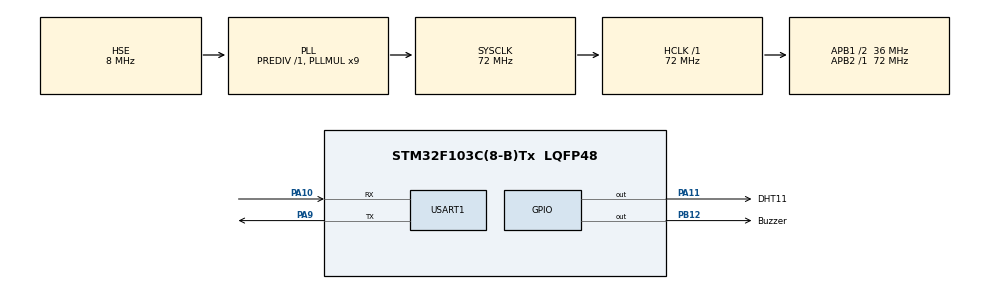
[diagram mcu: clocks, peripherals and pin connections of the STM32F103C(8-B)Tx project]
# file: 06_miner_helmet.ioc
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Mcu.Family=STM32F1
Mcu.Name=STM32F103C(8-B)Tx
Mcu.Package=LQFP48
NVIC.PriorityGroup=NVIC_PRIORITYGROUP_4
PA10.Mode=Asynchronous
PA10.Signal=USART1_RX
PA11.GPIO_Label=DHT11
PA11.GPIO_PuPd=GPIO_PULLUP
PA11.GPIO_Speed=GPIO_SPEED_FREQ_HIGH
PA11.PinState=GPIO_PIN_SET
PA11.Signal=GPIO_Output
PA13.Mode=Serial_Wire
PA13.Signal=SYS_JTMS-SWDIO
PA14.Mode=Serial_Wire
PA14.Signal=SYS_JTCK-SWCLK
PA9.Mode=Asynchronous
PA9.Signal=USART1_TX
PB12.GPIO_Label=Buzzer
PB12.GPIO_PuPd=GPIO_PULLUP
PB12.GPIO_Speed=GPIO_SPEED_FREQ_LOW
PB12.PinState=GPIO_PIN_SET
PB12.Signal=GPIO_Output
PC14-OSC32_IN.Mode=LSE-External-Oscillator
PC14-OSC32_IN.Signal=RCC_OSC32_IN
PC15-OSC32_OUT.Mode=LSE-External-Oscillator
PC15-OSC32_OUT.Signal=RCC_OSC32_OUT
PD0-OSC_IN.Mode=HSE-External-Oscillator
PD0-OSC_IN.Signal=RCC_OSC_IN
PD1-OSC_OUT.Mode=HSE-External-Oscillator
PD1-OSC_OUT.Signal=RCC_OSC_OUT
ProjectManager.HeapSize=0x200
ProjectManager.StackSize=0x400
ProjectManager.TargetToolchain=MDK-ARM V5.32
RCC.AHBFreq_Value=72000000
RCC.APB1CLKDivider=RCC_HCLK_DIV2
RCC.APB1Freq_Value=36000000
RCC.APB1TimFreq_Value=72000000
RCC.APB2Freq_Value=72000000
RCC.APB2TimFreq_Value=72000000
RCC.HCLKFreq_Value=72000000
RCC.PLLMUL=RCC_PLL_MUL9
RCC.PLLSourceVirtual=RCC_PLLSOURCE_HSE
RCC.SYSCLKFreq_VALUE=72000000
RCC.SYSCLKSource=RCC_SYSCLKSOURCE_PLLCLK
RCC.USBFreq_Value=72000000
TIM2.Prescaler=72-1
USART1.VirtualMode=VM_ASYNC
VP_TIM2_VS_ClockSourceINT.Mode=Internal
board=custom

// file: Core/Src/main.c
/* USER CODE BEGIN Header */
/**
 ******************************************************************************
 * @file           : main.c
 * @brief          : Main program body
 ******************************************************************************
 * @attention
 *
 * Copyright (c) 2025 STMicroelectronics.
 * All rights reserved.
 *
 * This software is licensed under terms that can be found in the LICENSE file
 * in the root directory of this software component.
 * If no LICENSE file comes with this software, it is provided AS-IS.
 *
 ******************************************************************************
 */
/* USER CODE END Header */
#include "main.h"
#include "tim.h"
#include "usart.h"
#include "gpio.h"

/* USER CODE BEGIN Includes */
#include "bsp_dht11.h"
/* USER CODE END Includes */

void SystemClock_Config(void);
/* USER CODE BEGIN PFP */
void delay_us(uint32_t Delay);
/* USER CODE END PFP */

int main(void)
{

  /* MCU Configuration--------------------------------------------------------*/

  /* Reset of all peripherals, Initializes the Flash interface and the Systick. */
  HAL_Init();

  /* Configure the system clock */
  SystemClock_Config();

  /* Initialize all configured peripherals */
  MX_GPIO_Init();
  MX_USART1_UART_Init();
  MX_TIM2_Init();
  /* USER CODE BEGIN 2 */
  uint8_t t = 0, h = 0;
  DHT11_Send();
  while (Is_DHT11_ACK())
  {
    printf("error\r\n");
    HAL_Delay(1000);
  }
  printf("success\r\n");
  // HAL_GPIO_WritePin(Buzzer_GPIO_Port, Buzzer_Pin, GPIO_PIN_RESET);
  /* USER CODE END 2 */

  /* Infinite loop */
  while (1)
  {
    DHT11_Data(&h,&t);
    printf("HUMI: %d , TEMP: %d\r\n",h,t);
    /* USER CODE BEGIN 3 */

    // /* Unit test 1: Buzzer test */
    // // Read the buzzer pin state and print it
    // printf("pin state:%d\n", HAL_GPIO_ReadPin(Buzzer_GPIO_Port, Buzzer_Pin));
    // // Toggle the buzzer pin state
    // HAL_GPIO_TogglePin(Buzzer_GPIO_Port, Buzzer_Pin);

    HAL_Delay(1000);
  }
  /* USER CODE END 3 */
}

void SystemClock_Config(void)
{
  RCC_OscInitTypeDef RCC_OscInitStruct = {0};
  RCC_ClkInitTypeDef RCC_ClkInitStruct = {0};

  /** Initializes the RCC Oscillators according to the specified parameters
   * in the RCC_OscInitTypeDef structure.
   */
  RCC_OscInitStruct.OscillatorType = RCC_OSCILLATORTYPE_HSE;
  RCC_OscInitStruct.HSEState = RCC_HSE_ON;
  RCC_OscInitStruct.HSEPredivValue = RCC_HSE_PREDIV_DIV1;
  RCC_OscInitStruct.HSIState = RCC_HSI_ON;
  RCC_OscInitStruct.PLL.PLLState = RCC_PLL_ON;
  RCC_OscInitStruct.PLL.PLLSource = RCC_PLLSOURCE_HSE;
  RCC_OscInitStruct.PLL.PLLMUL = RCC_PLL_MUL9;
  if (HAL_RCC_OscConfig(&RCC_OscInitStruct) != HAL_OK)
  {
    Error_Handler();
  }

  /** Initializes the CPU, AHB and APB buses clocks
   */
  RCC_ClkInitStruct.ClockType = RCC_CLOCKTYPE_HCLK | RCC_CLOCKTYPE_SYSCLK | RCC_CLOCKTYPE_PCLK1 | RCC_CLOCKTYPE_PCLK2;
  RCC_ClkInitStruct.SYSCLKSource = RCC_SYSCLKSOURCE_PLLCLK;
  RCC_ClkInitStruct.AHBCLKDivider = RCC_SYSCLK_DIV1;
  RCC_ClkInitStruct.APB1CLKDivider = RCC_HCLK_DIV2;
  RCC_ClkInitStruct.APB2CLKDivider = RCC_HCLK_DIV1;

  if (HAL_RCC_ClockConfig(&RCC_ClkInitStruct, FLASH_LATENCY_2) != HAL_OK)
  {
    Error_Handler();
  }
}

/* USER CODE BEGIN 4 */
void delay_us(uint32_t Delay)
{
  //__ indicate that these macros or variables are used internally by the library
  // and should not be modified or redefined directly by the user.
  __HAL_TIM_SET_COUNTER(&htim2, 0);             // 设置定时器当前计数寄存器为0
  __HAL_TIM_ENABLE(&htim2);                     // 开始计数
  while (__HAL_TIM_GET_COUNTER(&htim2) < Delay) // 延时
  {
  }
  __HAL_TIM_DISABLE(&htim2); // 延时完毕，关闭定时器
}
/* USER CODE END 4 */

void Error_Handler(void)
{
  __disable_irq();
  while (1)
  {
  }
}
